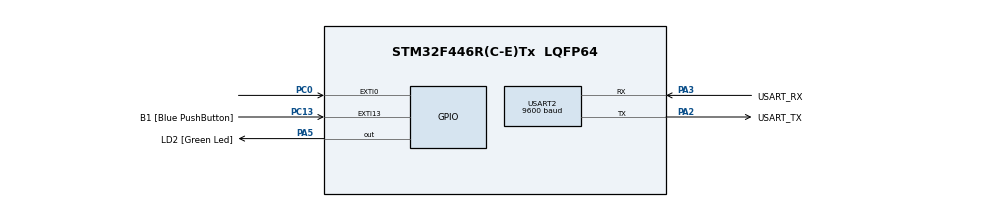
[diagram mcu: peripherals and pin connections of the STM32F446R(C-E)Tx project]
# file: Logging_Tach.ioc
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Mcu.Family=STM32F4
Mcu.Name=STM32F446R(C-E)Tx
Mcu.Package=LQFP64
NVIC.EXTI0_IRQn=true\:0\:0\:false\:false\:true\:true
NVIC.EXTI15_10_IRQn=true\:0\:0\:false\:false\:true\:true
NVIC.PriorityGroup=NVIC_PRIORITYGROUP_0
NVIC.TIM6_DAC_IRQn=true\:0\:0\:false\:false\:true\:true
NVIC.USART2_IRQn=true\:0\:0\:false\:false\:true\:true
PA13.GPIO_Label=TMS
PA13.Mode=Serial_Wire
PA13.Signal=SYS_JTMS-SWDIO
PA14.GPIO_Label=TCK
PA14.Mode=Serial_Wire
PA14.Signal=SYS_JTCK-SWCLK
PA2.GPIO_Label=USART_TX
PA2.Mode=Asynchronous
PA2.Signal=USART2_TX
PA3.GPIO_Label=USART_RX
PA3.Mode=Asynchronous
PA3.Signal=USART2_RX
PA5.GPIO_Label=LD2 [Green Led]
PA5.Signal=GPIO_Output
PB3.GPIO_Label=SWO
PB3.Signal=SYS_JTDO-SWO
PC0.GPIO_ModeDefaultEXTI=GPIO_MODE_IT_FALLING
PC0.GPIO_PuPd=GPIO_PULLUP
PC0.Signal=GPXTI0
PC13.GPIO_Label=B1 [Blue PushButton]
PC13.GPIO_ModeDefaultEXTI=GPIO_MODE_IT_FALLING
PC13.Signal=GPXTI13
PC14-OSC32_IN.Mode=LSE-External-Oscillator
PC14-OSC32_IN.Signal=RCC_OSC32_IN
PC15-OSC32_OUT.Mode=LSE-External-Oscillator
PC15-OSC32_OUT.Signal=RCC_OSC32_OUT
PH0-OSC_IN.Mode=HSE-External-Oscillator
PH0-OSC_IN.Signal=RCC_OSC_IN
PH1-OSC_OUT.Mode=HSE-External-Oscillator
PH1-OSC_OUT.Signal=RCC_OSC_OUT
ProjectManager.HeapSize=0x200
ProjectManager.StackSize=0x400
ProjectManager.TargetToolchain=EWARM V7
RCC.48MHZClocksFreq_Value=84000000
RCC.AHBFreq_Value=84000000
RCC.APB1CLKDivider=RCC_HCLK_DIV2
RCC.APB1Freq_Value=42000000
RCC.APB1TimFreq_Value=84000000
RCC.APB2Freq_Value=84000000
RCC.APB2TimFreq_Value=84000000
RCC.CortexFreq_Value=84000000
RCC.FLatency-AdvancedSettings=FLASH_LATENCY_2
RCC.HCLKFreq_Value=84000000
RCC.HSE_VALUE=8000000
RCC.HSI_VALUE=16000000
RCC.PLLN=336
RCC.PLLP=RCC_PLLP_DIV4
RCC.SYSCLKFreq_VALUE=84000000
RCC.SYSCLKSource=RCC_SYSCLKSOURCE_PLLCLK
RCC.USBFreq_Value=168000000
RCC.VCOOutputFreq_Value=336000000
TIM6.Period=10
TIM6.Prescaler=83
TIM6.TIM_MasterOutputTrigger=TIM_TRGO_UPDATE
USART2.BaudRate=9600
USART2.VirtualMode=VM_ASYNC
VP_TIM6_VS_ClockSourceINT.Mode=Enable_Timer
board=NUCLEO-F446RE

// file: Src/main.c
/**
  ******************************************************************************
  * @file           : main.c
  * @brief          : Main program body
  ******************************************************************************
  ** This notice applies to any and all portions of this file
  * that are not between comment pairs USER CODE BEGIN and
  * USER CODE END. Other portions of this file, whether
  * inserted by the user or by software development tools
  * are owned by their respective copyright owners.
  *
  * COPYRIGHT(c) 2018 STMicroelectronics
  *
  * Redistribution and use in source and binary forms, with or without modification,
  * are permitted provided that the following conditions are met:
  *   1. Redistributions of source code must retain the above copyright notice,
  *      this list of conditions and the following disclaimer.
  *   2. Redistributions in binary form must reproduce the above copyright notice,
  *      this list of conditions and the following disclaimer in the documentation
  *      and/or other materials provided with the distribution.
  *   3. Neither the name of STMicroelectronics nor the names of its contributors
  *      may be used to endorse or promote products derived from this software
  *      without specific prior written permission.
  *
  * THIS SOFTWARE IS PROVIDED BY THE COPYRIGHT HOLDERS AND CONTRIBUTORS "AS IS"
  * AND ANY EXPRESS OR IMPLIED WARRANTIES, INCLUDING, BUT NOT LIMITED TO, THE
  * IMPLIED WARRANTIES OF MERCHANTABILITY AND FITNESS FOR A PARTICULAR PURPOSE ARE
  * DISCLAIMED. IN NO EVENT SHALL THE COPYRIGHT HOLDER OR CONTRIBUTORS BE LIABLE
  * FOR ANY DIRECT, INDIRECT, INCIDENTAL, SPECIAL, EXEMPLARY, OR CONSEQUENTIAL
  * DAMAGES (INCLUDING, BUT NOT LIMITED TO, PROCUREMENT OF SUBSTITUTE GOODS OR
  * SERVICES; LOSS OF USE, DATA, OR PROFITS; OR BUSINESS INTERRUPTION) HOWEVER
  * CAUSED AND ON ANY THEORY OF LIABILITY, WHETHER IN CONTRACT, STRICT LIABILITY,
  * OR TORT (INCLUDING NEGLIGENCE OR OTHERWISE) ARISING IN ANY WAY OUT OF THE USE
  * OF THIS SOFTWARE, EVEN IF ADVISED OF THE POSSIBILITY OF SUCH DAMAGE.
  *
  ******************************************************************************
  */
#include "main.h"

/* USER CODE BEGIN PV */
/* Private variables ---------------------------------------------------------*/

/* USER CODE END PV */

static void LL_Init(void);
void SystemClock_Config(void);
static void MX_GPIO_Init(void);
static void MX_USART2_UART_Init(void);
static void MX_TIM6_Init(void);

/* USER CODE BEGIN PFP */
/* Private function prototypes -----------------------------------------------*/

/* USER CODE END PFP */

int main(void)
{

  /* MCU Configuration----------------------------------------------------------*/

  /* Reset of all peripherals, Initializes the Flash interface and the Systick. */
  LL_Init();

  /* Configure the system clock */
  SystemClock_Config();

  /* Initialize all configured peripherals */
  MX_GPIO_Init();
  MX_USART2_UART_Init();
  MX_TIM6_Init();
  /* USER CODE BEGIN 2 */
  LL_TIM_EnableCounter(TIM6);
  LL_TIM_EnableIT_UPDATE(TIM6);
  /* USER CODE END 2 */

  /* Infinite loop */
  while (1)
  {

  }

}
static void LL_Init(void)
{

  LL_APB2_GRP1_EnableClock(LL_APB2_GRP1_PERIPH_SYSCFG);
  LL_APB1_GRP1_EnableClock(LL_APB1_GRP1_PERIPH_PWR);

  NVIC_SetPriorityGrouping(NVIC_PRIORITYGROUP_0);

  /* System interrupt init*/
  /* MemoryManagement_IRQn interrupt configuration */
  NVIC_SetPriority(MemoryManagement_IRQn, NVIC_EncodePriority(NVIC_GetPriorityGrouping(),0, 0));
  /* BusFault_IRQn interrupt configuration */
  NVIC_SetPriority(BusFault_IRQn, NVIC_EncodePriority(NVIC_GetPriorityGrouping(),0, 0));
  /* UsageFault_IRQn interrupt configuration */
  NVIC_SetPriority(UsageFault_IRQn, NVIC_EncodePriority(NVIC_GetPriorityGrouping(),0, 0));
  /* SVCall_IRQn interrupt configuration */
  NVIC_SetPriority(SVCall_IRQn, NVIC_EncodePriority(NVIC_GetPriorityGrouping(),0, 0));
  /* DebugMonitor_IRQn interrupt configuration */
  NVIC_SetPriority(DebugMonitor_IRQn, NVIC_EncodePriority(NVIC_GetPriorityGrouping(),0, 0));
  /* PendSV_IRQn interrupt configuration */
  NVIC_SetPriority(PendSV_IRQn, NVIC_EncodePriority(NVIC_GetPriorityGrouping(),0, 0));
  /* SysTick_IRQn interrupt configuration */
  NVIC_SetPriority(SysTick_IRQn, NVIC_EncodePriority(NVIC_GetPriorityGrouping(),0, 0));

}

void SystemClock_Config(void)
{

  LL_FLASH_SetLatency(LL_FLASH_LATENCY_2);

   if(LL_FLASH_GetLatency() != LL_FLASH_LATENCY_2)
  {
  Error_Handler();
  }
  LL_PWR_SetRegulVoltageScaling(LL_PWR_REGU_VOLTAGE_SCALE3);

  LL_PWR_DisableOverDriveMode();

  LL_RCC_HSI_SetCalibTrimming(16);

  LL_RCC_HSI_Enable();

   /* Wait till HSI is ready */
  while(LL_RCC_HSI_IsReady() != 1)
  {

  }
  LL_RCC_PLL_ConfigDomain_SYS(LL_RCC_PLLSOURCE_HSI, LL_RCC_PLLM_DIV_16, 336, LL_RCC_PLLP_DIV_4);

  LL_RCC_PLL_Enable();

   /* Wait till PLL is ready */
  while(LL_RCC_PLL_IsReady() != 1)
  {

  }
  LL_RCC_SetAHBPrescaler(LL_RCC_SYSCLK_DIV_1);

  LL_RCC_SetAPB1Prescaler(LL_RCC_APB1_DIV_2);

  LL_RCC_SetAPB2Prescaler(LL_RCC_APB2_DIV_1);

  LL_RCC_SetSysClkSource(LL_RCC_SYS_CLKSOURCE_PLL);

   /* Wait till System clock is ready */
  while(LL_RCC_GetSysClkSource() != LL_RCC_SYS_CLKSOURCE_STATUS_PLL)
  {

  }
  LL_Init1msTick(84000000);

  LL_SYSTICK_SetClkSource(LL_SYSTICK_CLKSOURCE_HCLK);

  LL_SetSystemCoreClock(84000000);

  LL_RCC_SetTIMPrescaler(LL_RCC_TIM_PRESCALER_TWICE);

  /* SysTick_IRQn interrupt configuration */
  NVIC_SetPriority(SysTick_IRQn, NVIC_EncodePriority(NVIC_GetPriorityGrouping(),0, 0));
}

/* TIM6 init function */
static void MX_TIM6_Init(void)
{

  LL_TIM_InitTypeDef TIM_InitStruct;

  /* Peripheral clock enable */
  LL_APB1_GRP1_EnableClock(LL_APB1_GRP1_PERIPH_TIM6);

  /* TIM6 interrupt Init */
  NVIC_SetPriority(TIM6_DAC_IRQn, NVIC_EncodePriority(NVIC_GetPriorityGrouping(),0, 0));
  NVIC_EnableIRQ(TIM6_DAC_IRQn);

  TIM_InitStruct.Prescaler = 83;
  TIM_InitStruct.CounterMode = LL_TIM_COUNTERMODE_UP;
  TIM_InitStruct.Autoreload = 10;
  LL_TIM_Init(TIM6, &TIM_InitStruct);

  LL_TIM_SetTriggerOutput(TIM6, LL_TIM_TRGO_UPDATE);

  LL_TIM_DisableMasterSlaveMode(TIM6);

}

/* USART2 init function */
static void MX_USART2_UART_Init(void)
{

  LL_USART_InitTypeDef USART_InitStruct;

  LL_GPIO_InitTypeDef GPIO_InitStruct;

  /* Peripheral clock enable */
  LL_APB1_GRP1_EnableClock(LL_APB1_GRP1_PERIPH_USART2);

  /**USART2 GPIO Configuration
  PA2   ------> USART2_TX
  PA3   ------> USART2_RX
  */
  GPIO_InitStruct.Pin = USART_TX_Pin|USART_RX_Pin;
  GPIO_InitStruct.Mode = LL_GPIO_MODE_ALTERNATE;
  GPIO_InitStruct.Speed = LL_GPIO_SPEED_FREQ_VERY_HIGH;
  GPIO_InitStruct.OutputType = LL_GPIO_OUTPUT_PUSHPULL;
  GPIO_InitStruct.Pull = LL_GPIO_PULL_UP;
  GPIO_InitStruct.Alternate = LL_GPIO_AF_7;
  LL_GPIO_Init(GPIOA, &GPIO_InitStruct);

  /* USART2 interrupt Init */
  NVIC_SetPriority(USART2_IRQn, NVIC_EncodePriority(NVIC_GetPriorityGrouping(),0, 0));
  NVIC_EnableIRQ(USART2_IRQn);

  USART_InitStruct.BaudRate = 9600;
  USART_InitStruct.DataWidth = LL_USART_DATAWIDTH_8B;
  USART_InitStruct.StopBits = LL_USART_STOPBITS_1;
  USART_InitStruct.Parity = LL_USART_PARITY_NONE;
  USART_InitStruct.TransferDirection = LL_USART_DIRECTION_TX_RX;
  USART_InitStruct.HardwareFlowControl = LL_USART_HWCONTROL_NONE;
  USART_InitStruct.OverSampling = LL_USART_OVERSAMPLING_16;
  LL_USART_Init(USART2, &USART_InitStruct);

  LL_USART_ConfigAsyncMode(USART2);

  LL_USART_Enable(USART2);

}

/** Configure pins as
        * Analog
        * Input
        * Output
        * EVENT_OUT
        * EXTI
*/
static void MX_GPIO_Init(void)
{

  LL_GPIO_InitTypeDef GPIO_InitStruct;
  LL_EXTI_InitTypeDef EXTI_InitStruct;

  /* GPIO Ports Clock Enable */
  LL_AHB1_GRP1_EnableClock(LL_AHB1_GRP1_PERIPH_GPIOC);
  LL_AHB1_GRP1_EnableClock(LL_AHB1_GRP1_PERIPH_GPIOH);
  LL_AHB1_GRP1_EnableClock(LL_AHB1_GRP1_PERIPH_GPIOA);
  LL_AHB1_GRP1_EnableClock(LL_AHB1_GRP1_PERIPH_GPIOB);

  /**/
  LL_GPIO_ResetOutputPin(LD2_GPIO_Port, LD2_Pin);

  /**/
  LL_SYSCFG_SetEXTISource(LL_SYSCFG_EXTI_PORTC, LL_SYSCFG_EXTI_LINE13);

  /**/
  LL_SYSCFG_SetEXTISource(LL_SYSCFG_EXTI_PORTC, LL_SYSCFG_EXTI_LINE0);

  /**/
  EXTI_InitStruct.Line_0_31 = LL_EXTI_LINE_13;
  EXTI_InitStruct.LineCommand = ENABLE;
  EXTI_InitStruct.Mode = LL_EXTI_MODE_IT;
  EXTI_InitStruct.Trigger = LL_EXTI_TRIGGER_FALLING;
  LL_EXTI_Init(&EXTI_InitStruct);

  /**/
  EXTI_InitStruct.Line_0_31 = LL_EXTI_LINE_0;
  EXTI_InitStruct.LineCommand = ENABLE;
  EXTI_InitStruct.Mode = LL_EXTI_MODE_IT;
  EXTI_InitStruct.Trigger = LL_EXTI_TRIGGER_FALLING;
  LL_EXTI_Init(&EXTI_InitStruct);

  /**/
  LL_GPIO_SetPinPull(B1_GPIO_Port, B1_Pin, LL_GPIO_PULL_NO);

  /**/
  LL_GPIO_SetPinPull(GPIOC, LL_GPIO_PIN_0, LL_GPIO_PULL_UP);

  /**/
  LL_GPIO_SetPinMode(B1_GPIO_Port, B1_Pin, LL_GPIO_MODE_INPUT);

  /**/
  LL_GPIO_SetPinMode(GPIOC, LL_GPIO_PIN_0, LL_GPIO_MODE_INPUT);

  /**/
  GPIO_InitStruct.Pin = LD2_Pin;
  GPIO_InitStruct.Mode = LL_GPIO_MODE_OUTPUT;
  GPIO_InitStruct.Speed = LL_GPIO_SPEED_FREQ_LOW;
  GPIO_InitStruct.OutputType = LL_GPIO_OUTPUT_PUSHPULL;
  GPIO_InitStruct.Pull = LL_GPIO_PULL_NO;
  LL_GPIO_Init(LD2_GPIO_Port, &GPIO_InitStruct);

  /* EXTI interrupt init*/
  NVIC_SetPriority(EXTI0_IRQn, NVIC_EncodePriority(NVIC_GetPriorityGrouping(),0, 0));
  NVIC_EnableIRQ(EXTI0_IRQn);
  NVIC_SetPriority(EXTI15_10_IRQn, NVIC_EncodePriority(NVIC_GetPriorityGrouping(),0, 0));
  NVIC_EnableIRQ(EXTI15_10_IRQn);

}

void _Error_Handler(char *file, int line)
{
  while(1)
  {
  }
}

/************************ (C) COPYRIGHT STMicroelectronics *****END OF FILE****/
